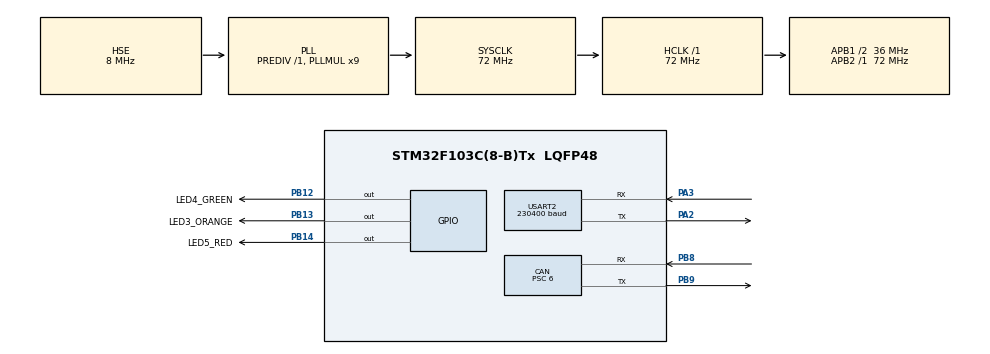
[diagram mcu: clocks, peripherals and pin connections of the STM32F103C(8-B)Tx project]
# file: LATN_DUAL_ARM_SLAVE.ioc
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CAN.BS1=CAN_BS1_2TQ
CAN.BS2=CAN_BS2_3TQ
CAN.CalculateBaudRate=999999
CAN.CalculateTimeBit=1000
CAN.CalculateTimeQuantum=166.66666666666669
CAN.Prescaler=6
Dma.Request0=USART2_RX
Dma.Request1=USART2_TX
Dma.USART2_RX.0.Direction=DMA_PERIPH_TO_MEMORY
Dma.USART2_RX.0.Instance=DMA1_Channel6
Dma.USART2_RX.0.MemDataAlignment=DMA_MDATAALIGN_BYTE
Dma.USART2_RX.0.MemInc=DMA_MINC_ENABLE
Dma.USART2_RX.0.Mode=DMA_NORMAL
Dma.USART2_RX.0.PeriphDataAlignment=DMA_PDATAALIGN_BYTE
Dma.USART2_RX.0.PeriphInc=DMA_PINC_DISABLE
Dma.USART2_RX.0.Priority=DMA_PRIORITY_LOW
Dma.USART2_TX.1.Direction=DMA_MEMORY_TO_PERIPH
Dma.USART2_TX.1.Instance=DMA1_Channel7
Dma.USART2_TX.1.MemDataAlignment=DMA_MDATAALIGN_BYTE
Dma.USART2_TX.1.MemInc=DMA_MINC_ENABLE
Dma.USART2_TX.1.Mode=DMA_NORMAL
Dma.USART2_TX.1.PeriphDataAlignment=DMA_PDATAALIGN_BYTE
Dma.USART2_TX.1.PeriphInc=DMA_PINC_DISABLE
Dma.USART2_TX.1.Priority=DMA_PRIORITY_LOW
Mcu.Family=STM32F1
Mcu.Name=STM32F103C(8-B)Tx
Mcu.Package=LQFP48
NVIC.DMA1_Channel6_IRQn=true\:0\:0\:false\:false\:true\:false\:true\:true
NVIC.DMA1_Channel7_IRQn=true\:0\:0\:false\:false\:true\:false\:true\:true
NVIC.PriorityGroup=NVIC_PRIORITYGROUP_4
NVIC.TIM2_IRQn=true\:0\:0\:false\:false\:true\:true\:true\:true
NVIC.USART2_IRQn=true\:0\:0\:false\:false\:true\:true\:true\:true
NVIC.USB_LP_CAN1_RX0_IRQn=true\:0\:0\:false\:false\:true\:true\:true\:true
PA13.Mode=Serial_Wire
PA13.Signal=SYS_JTMS-SWDIO
PA14.Mode=Serial_Wire
PA14.Signal=SYS_JTCK-SWCLK
PA2.Mode=Asynchronous
PA2.Signal=USART2_TX
PA3.Mode=Asynchronous
PA3.Signal=USART2_RX
PB12.GPIO_Label=LED4_GREEN
PB12.Signal=GPIO_Output
PB13.GPIO_Label=LED3_ORANGE
PB13.Signal=GPIO_Output
PB14.GPIO_Label=LED5_RED
PB14.Signal=GPIO_Output
PB8.Mode=CAN_Activate
PB8.Signal=CAN_RX
PB9.Mode=CAN_Activate
PB9.Signal=CAN_TX
PD0-OSC_IN.Mode=HSE-External-Oscillator
PD0-OSC_IN.Signal=RCC_OSC_IN
PD1-OSC_OUT.Mode=HSE-External-Oscillator
PD1-OSC_OUT.Signal=RCC_OSC_OUT
ProjectManager.HeapSize=0x200
ProjectManager.StackSize=0x400
ProjectManager.TargetToolchain=STM32CubeIDE
RCC.AHBFreq_Value=72000000
RCC.APB1CLKDivider=RCC_HCLK_DIV2
RCC.APB1Freq_Value=36000000
RCC.APB1TimFreq_Value=72000000
RCC.APB2Freq_Value=72000000
RCC.APB2TimFreq_Value=72000000
RCC.HCLKFreq_Value=72000000
RCC.PLLMUL=RCC_PLL_MUL9
RCC.PLLSourceVirtual=RCC_PLLSOURCE_HSE
RCC.SYSCLKFreq_VALUE=72000000
RCC.SYSCLKSource=RCC_SYSCLKSOURCE_PLLCLK
RCC.USBFreq_Value=72000000
TIM2.Period=1000-1
TIM2.Prescaler=72-1
USART2.BaudRate=230400
USART2.VirtualMode=VM_ASYNC
VP_TIM2_VS_ClockSourceINT.Mode=Internal
board=custom

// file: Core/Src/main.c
/* USER CODE BEGIN Header */
/**
  ******************************************************************************
  * @file           : main.c
  * @brief          : Main program body
  ******************************************************************************
  * @attention
  *
  * Copyright (c) 2024 STMicroelectronics.
  * All rights reserved.
  *
  * This software is licensed under terms that can be found in the LICENSE file
  * in the root directory of this software component.
  * If no LICENSE file comes with this software, it is provided AS-IS.
  *
  ******************************************************************************
  */
/* USER CODE END Header */
#include "main.h"

/* USER CODE BEGIN Includes */
#include "LibraryHHInterface_Slave.h"
/* USER CODE END Includes */

CAN_HandleTypeDef hcan;

TIM_HandleTypeDef htim2;

UART_HandleTypeDef huart2;
DMA_HandleTypeDef hdma_usart2_rx;
DMA_HandleTypeDef hdma_usart2_tx;

void SystemClock_Config(void);
static void MX_GPIO_Init(void);
static void MX_DMA_Init(void);
static void MX_CAN_Init(void);
static void MX_TIM2_Init(void);
static void MX_USART2_UART_Init(void);

int main(void)
{

  /* MCU Configuration--------------------------------------------------------*/

  /* Reset of all peripherals, Initializes the Flash interface and the Systick. */
  HAL_Init();

  /* Configure the system clock */
  SystemClock_Config();

  /* Initialize all configured peripherals */
  MX_GPIO_Init();
  MX_DMA_Init();
  MX_CAN_Init();
  MX_TIM2_Init();
  MX_USART2_UART_Init();
  /* USER CODE BEGIN 2 */
	AppCommUART_UserSetup(&huart2, UART_NODE_MASTER);
	AppCommCAN_UserSetup(&hcan);
	HAL_CAN_Start(&hcan);

  /* USER CODE END 2 */

  /* Infinite loop */
  /* USER CODE BEGIN WHILE */

	 HAL_TIM_Base_Start_IT(&htim2);		// Start scheduling task
  while (1)
  {
//	AppPeriodTask_TaskCall();
	AppPeriodTask_StateMachineProcess();
    /* USER CODE END WHILE */

  }
}

void SystemClock_Config(void)
{
  RCC_OscInitTypeDef RCC_OscInitStruct = {0};
  RCC_ClkInitTypeDef RCC_ClkInitStruct = {0};

  /** Initializes the RCC Oscillators according to the specified parameters
  * in the RCC_OscInitTypeDef structure.
  */
  RCC_OscInitStruct.OscillatorType = RCC_OSCILLATORTYPE_HSE;
  RCC_OscInitStruct.HSEState = RCC_HSE_ON;
  RCC_OscInitStruct.HSEPredivValue = RCC_HSE_PREDIV_DIV1;
  RCC_OscInitStruct.HSIState = RCC_HSI_ON;
  RCC_OscInitStruct.PLL.PLLState = RCC_PLL_ON;
  RCC_OscInitStruct.PLL.PLLSource = RCC_PLLSOURCE_HSE;
  RCC_OscInitStruct.PLL.PLLMUL = RCC_PLL_MUL9;
  if (HAL_RCC_OscConfig(&RCC_OscInitStruct) != HAL_OK)
  {
    Error_Handler();
  }

  /** Initializes the CPU, AHB and APB buses clocks
  */
  RCC_ClkInitStruct.ClockType = RCC_CLOCKTYPE_HCLK|RCC_CLOCKTYPE_SYSCLK
                              |RCC_CLOCKTYPE_PCLK1|RCC_CLOCKTYPE_PCLK2;
  RCC_ClkInitStruct.SYSCLKSource = RCC_SYSCLKSOURCE_PLLCLK;
  RCC_ClkInitStruct.AHBCLKDivider = RCC_SYSCLK_DIV1;
  RCC_ClkInitStruct.APB1CLKDivider = RCC_HCLK_DIV2;
  RCC_ClkInitStruct.APB2CLKDivider = RCC_HCLK_DIV1;

  if (HAL_RCC_ClockConfig(&RCC_ClkInitStruct, FLASH_LATENCY_2) != HAL_OK)
  {
    Error_Handler();
  }
}

static void MX_CAN_Init(void)
{

  hcan.Instance = CAN1;
  hcan.Init.Prescaler = 6;
  hcan.Init.Mode = CAN_MODE_NORMAL;
  hcan.Init.SyncJumpWidth = CAN_SJW_1TQ;
  hcan.Init.TimeSeg1 = CAN_BS1_2TQ;
  hcan.Init.TimeSeg2 = CAN_BS2_3TQ;
  hcan.Init.TimeTriggeredMode = DISABLE;
  hcan.Init.AutoBusOff = DISABLE;
  hcan.Init.AutoWakeUp = DISABLE;
  hcan.Init.AutoRetransmission = DISABLE;
  hcan.Init.ReceiveFifoLocked = DISABLE;
  hcan.Init.TransmitFifoPriority = DISABLE;
  if (HAL_CAN_Init(&hcan) != HAL_OK)
  {
    Error_Handler();
  }

}

static void MX_TIM2_Init(void)
{

  TIM_ClockConfigTypeDef sClockSourceConfig = {0};
  TIM_MasterConfigTypeDef sMasterConfig = {0};

  htim2.Instance = TIM2;
  htim2.Init.Prescaler = 72-1;
  htim2.Init.CounterMode = TIM_COUNTERMODE_UP;
  htim2.Init.Period = 1000-1;
  htim2.Init.ClockDivision = TIM_CLOCKDIVISION_DIV1;
  htim2.Init.AutoReloadPreload = TIM_AUTORELOAD_PRELOAD_DISABLE;
  if (HAL_TIM_Base_Init(&htim2) != HAL_OK)
  {
    Error_Handler();
  }
  sClockSourceConfig.ClockSource = TIM_CLOCKSOURCE_INTERNAL;
  if (HAL_TIM_ConfigClockSource(&htim2, &sClockSourceConfig) != HAL_OK)
  {
    Error_Handler();
  }
  sMasterConfig.MasterOutputTrigger = TIM_TRGO_RESET;
  sMasterConfig.MasterSlaveMode = TIM_MASTERSLAVEMODE_DISABLE;
  if (HAL_TIMEx_MasterConfigSynchronization(&htim2, &sMasterConfig) != HAL_OK)
  {
    Error_Handler();
  }

}

static void MX_USART2_UART_Init(void)
{

  huart2.Instance = USART2;
  huart2.Init.BaudRate = 230400;
  huart2.Init.WordLength = UART_WORDLENGTH_8B;
  huart2.Init.StopBits = UART_STOPBITS_1;
  huart2.Init.Parity = UART_PARITY_NONE;
  huart2.Init.Mode = UART_MODE_TX_RX;
  huart2.Init.HwFlowCtl = UART_HWCONTROL_NONE;
  huart2.Init.OverSampling = UART_OVERSAMPLING_16;
  if (HAL_UART_Init(&huart2) != HAL_OK)
  {
    Error_Handler();
  }

}

static void MX_DMA_Init(void)
{

  /* DMA controller clock enable */
  __HAL_RCC_DMA1_CLK_ENABLE();

  /* DMA interrupt init */
  /* DMA1_Channel6_IRQn interrupt configuration */
  HAL_NVIC_SetPriority(DMA1_Channel6_IRQn, 0, 0);
  HAL_NVIC_EnableIRQ(DMA1_Channel6_IRQn);
  /* DMA1_Channel7_IRQn interrupt configuration */
  HAL_NVIC_SetPriority(DMA1_Channel7_IRQn, 0, 0);
  HAL_NVIC_EnableIRQ(DMA1_Channel7_IRQn);

}

static void MX_GPIO_Init(void)
{
  GPIO_InitTypeDef GPIO_InitStruct = {0};

  /* GPIO Ports Clock Enable */
  __HAL_RCC_GPIOD_CLK_ENABLE();
  __HAL_RCC_GPIOA_CLK_ENABLE();
  __HAL_RCC_GPIOB_CLK_ENABLE();

  /*Configure GPIO pin Output Level */
  HAL_GPIO_WritePin(GPIOB, LED4_GREEN_Pin|LED3_ORANGE_Pin|LED5_RED_Pin, GPIO_PIN_RESET);

  /*Configure GPIO pins : LED4_GREEN_Pin LED3_ORANGE_Pin LED5_RED_Pin */
  GPIO_InitStruct.Pin = LED4_GREEN_Pin|LED3_ORANGE_Pin|LED5_RED_Pin;
  GPIO_InitStruct.Mode = GPIO_MODE_OUTPUT_PP;
  GPIO_InitStruct.Pull = GPIO_NOPULL;
  GPIO_InitStruct.Speed = GPIO_SPEED_FREQ_LOW;
  HAL_GPIO_Init(GPIOB, &GPIO_InitStruct);

}

void Error_Handler(void)
{
  __disable_irq();
  while (1)
  {
  }
}
